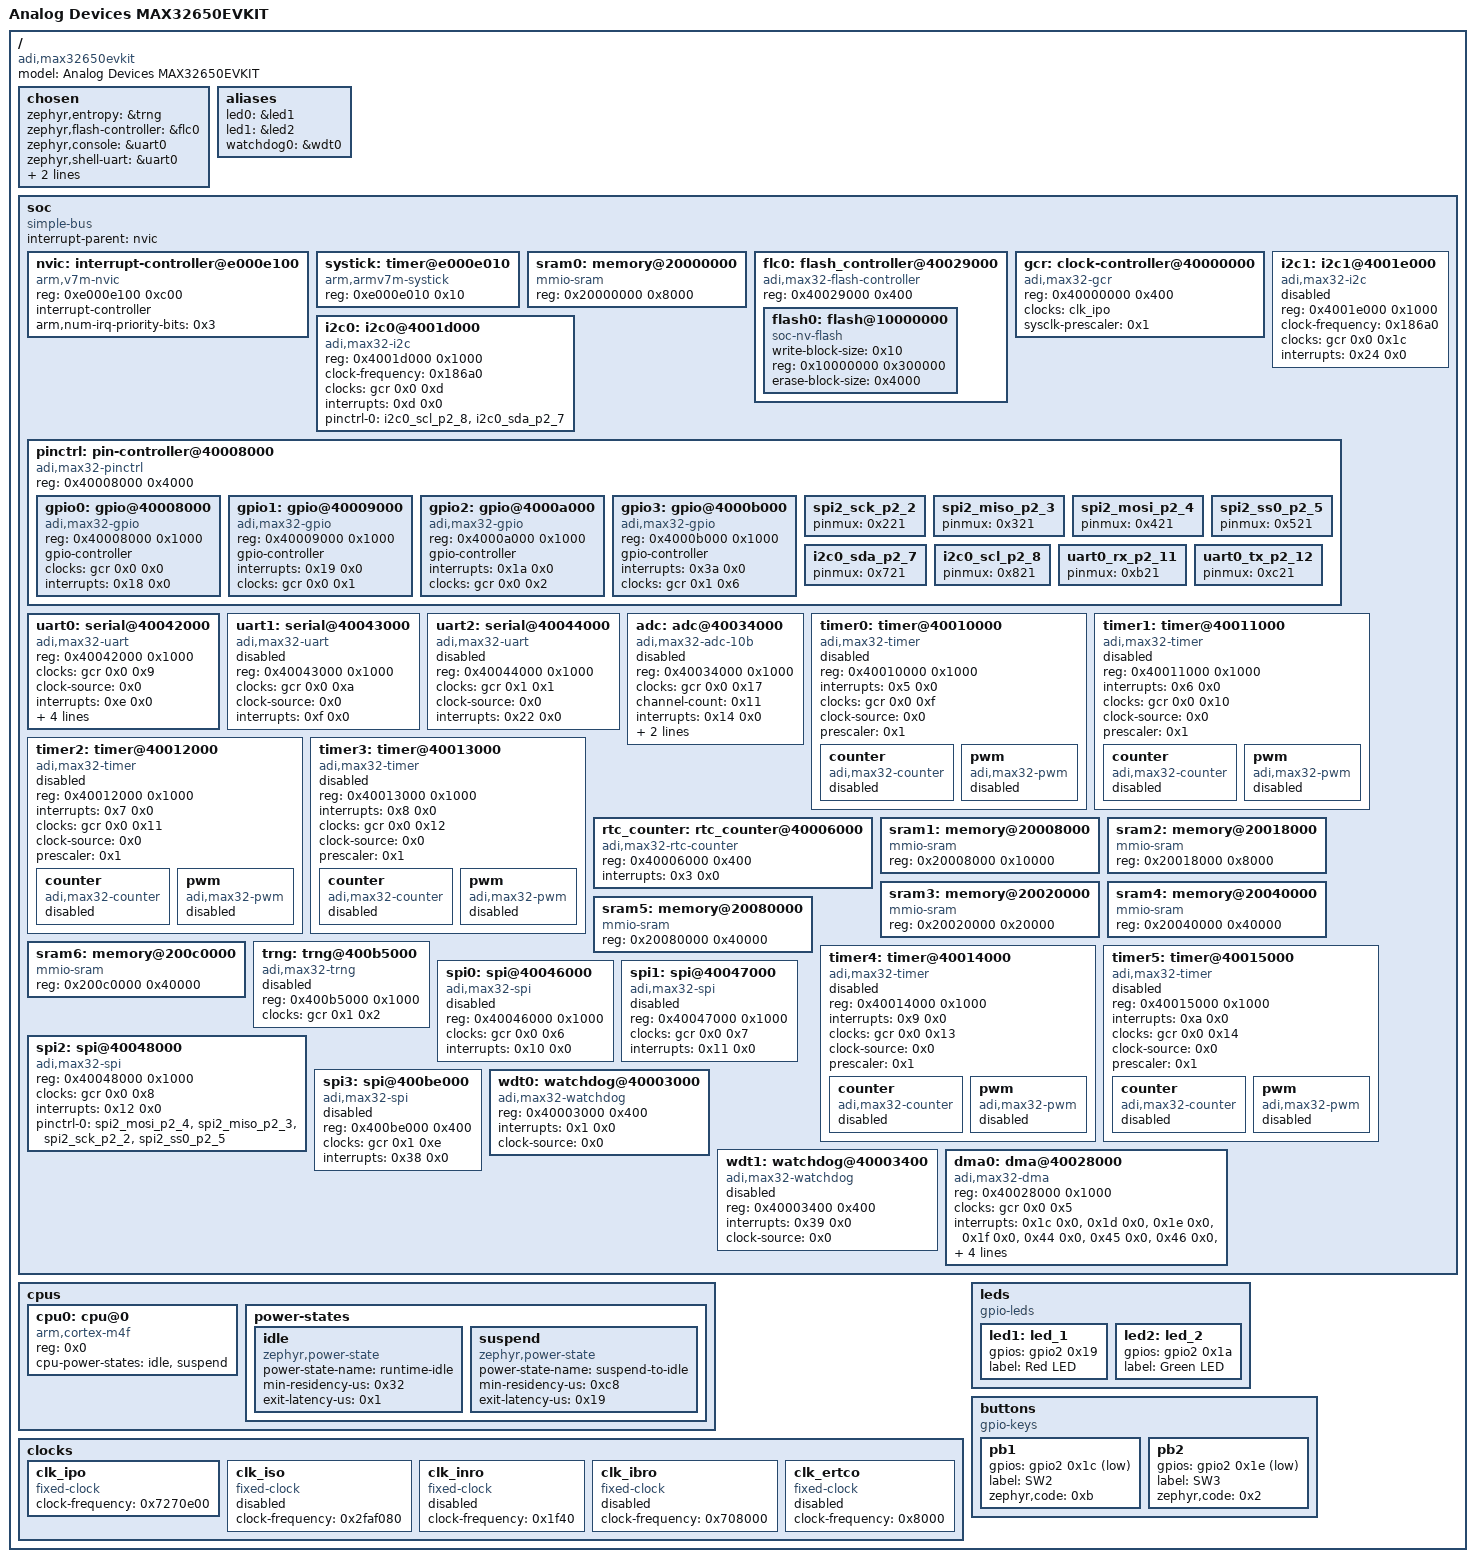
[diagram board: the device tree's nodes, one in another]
/dts-v1/;

/* node '/' defined in zephyr/dts/common/skeleton.dtsi:9 */
/ {
	#address-cells = < 0x1 >;               /* in zephyr/dts/common/skeleton.dtsi:10 */
	#size-cells = < 0x1 >;                  /* in zephyr/dts/common/skeleton.dtsi:11 */
	model = "Analog Devices MAX32650EVKIT"; /* in zephyr/boards/adi/max32650evkit/max32650evkit.dts:15 */
	compatible = "adi,max32650evkit";       /* in zephyr/boards/adi/max32650evkit/max32650evkit.dts:16 */

	/* node '/chosen' defined in zephyr/dts/common/skeleton.dtsi:13 */
	chosen {
		zephyr,entropy = &trng;          /* in zephyr/dts/arm/adi/max32/max32xxx.dtsi:17 */
		zephyr,flash-controller = &flc0; /* in zephyr/dts/arm/adi/max32/max32xxx.dtsi:18 */
		zephyr,console = &uart0;         /* in zephyr/boards/adi/max32650evkit/max32650evkit.dts:19 */
		zephyr,shell-uart = &uart0;      /* in zephyr/boards/adi/max32650evkit/max32650evkit.dts:20 */
		zephyr,sram = &sram4;            /* in zephyr/boards/adi/max32650evkit/max32650evkit.dts:21 */
		zephyr,flash = &flash0;          /* in zephyr/boards/adi/max32650evkit/max32650evkit.dts:22 */
	};

	/* node '/aliases' defined in zephyr/dts/common/skeleton.dtsi:15 */
	aliases {
		led0 = &led1;      /* in zephyr/boards/adi/max32650evkit/max32650evkit.dts:57 */
		led1 = &led2;      /* in zephyr/boards/adi/max32650evkit/max32650evkit.dts:58 */
		watchdog0 = &wdt0; /* in zephyr/boards/adi/max32650evkit/max32650evkit.dts:59 */
	};

	/* node '/soc' defined in zephyr/dts/arm/armv7-m.dtsi:6 */
	soc {
		#address-cells = < 0x1 >;     /* in zephyr/dts/arm/armv7-m.dtsi:7 */
		#size-cells = < 0x1 >;        /* in zephyr/dts/arm/armv7-m.dtsi:8 */
		compatible = "simple-bus";    /* in zephyr/dts/arm/armv7-m.dtsi:9 */
		interrupt-parent = < &nvic >; /* in zephyr/dts/arm/armv7-m.dtsi:10 */
		ranges;                       /* in zephyr/dts/arm/armv7-m.dtsi:11 */

		/* node '/soc/interrupt-controller@e000e100' defined in zephyr/dts/arm/armv7-m.dtsi:13 */
		nvic: interrupt-controller@e000e100 {
			#address-cells = < 0x1 >;            /* in zephyr/dts/arm/armv7-m.dtsi:14 */
			compatible = "arm,v7m-nvic";         /* in zephyr/dts/arm/armv7-m.dtsi:15 */
			reg = < 0xe000e100 0xc00 >;          /* in zephyr/dts/arm/armv7-m.dtsi:16 */
			interrupt-controller;                /* in zephyr/dts/arm/armv7-m.dtsi:17 */
			#interrupt-cells = < 0x2 >;          /* in zephyr/dts/arm/armv7-m.dtsi:18 */
			arm,num-irq-priority-bits = < 0x3 >; /* in zephyr/dts/arm/adi/max32/max32xxx.dtsi:337 */
			phandle = < 0x1 >;                   /* in zephyr/dts/arm/armv7-m.dtsi:10 */
		};

		/* node '/soc/timer@e000e010' defined in zephyr/dts/arm/armv7-m.dtsi:21 */
		systick: timer@e000e010 {
			compatible = "arm,armv7m-systick"; /* in zephyr/dts/arm/armv7-m.dtsi:22 */
			reg = < 0xe000e010 0x10 >;         /* in zephyr/dts/arm/armv7-m.dtsi:23 */
		};

		/* node '/soc/memory@20000000' defined in zephyr/dts/arm/adi/max32/max32xxx.dtsi:98 */
		sram0: memory@20000000 {
			compatible = "mmio-sram";    /* in zephyr/dts/arm/adi/max32/max32xxx.dtsi:99 */
			reg = < 0x20000000 0x8000 >; /* in zephyr/dts/arm/adi/max32/max32xxx.dtsi:100 */
		};

		/* node '/soc/flash_controller@40029000' defined in zephyr/dts/arm/adi/max32/max32xxx.dtsi:103 */
		flc0: flash_controller@40029000 {
			compatible = "adi,max32-flash-controller"; /* in zephyr/dts/arm/adi/max32/max32xxx.dtsi:104 */
			reg = < 0x40029000 0x400 >;                /* in zephyr/dts/arm/adi/max32/max32xxx.dtsi:105 */
			#address-cells = < 0x1 >;                  /* in zephyr/dts/arm/adi/max32/max32xxx.dtsi:107 */
			#size-cells = < 0x1 >;                     /* in zephyr/dts/arm/adi/max32/max32xxx.dtsi:108 */
			status = "okay";                           /* in zephyr/dts/arm/adi/max32/max32xxx.dtsi:109 */

			/* node '/soc/flash_controller@40029000/flash@10000000' defined in zephyr/dts/arm/adi/max32/max32xxx.dtsi:111 */
			flash0: flash@10000000 {
				compatible = "soc-nv-flash";   /* in zephyr/dts/arm/adi/max32/max32xxx.dtsi:112 */
				write-block-size = < 0x10 >;   /* in zephyr/dts/arm/adi/max32/max32xxx.dtsi:114 */
				reg = < 0x10000000 0x300000 >; /* in zephyr/dts/arm/adi/max32/max32650.dtsi:12 */
				erase-block-size = < 0x4000 >; /* in zephyr/dts/arm/adi/max32/max32650.dtsi:13 */
			};
		};

		/* node '/soc/clock-controller@40000000' defined in zephyr/dts/arm/adi/max32/max32xxx.dtsi:119 */
		gcr: clock-controller@40000000 {
			reg = < 0x40000000 0x400 >;   /* in zephyr/dts/arm/adi/max32/max32xxx.dtsi:120 */
			compatible = "adi,max32-gcr"; /* in zephyr/dts/arm/adi/max32/max32xxx.dtsi:121 */
			#clock-cells = < 0x2 >;       /* in zephyr/dts/arm/adi/max32/max32xxx.dtsi:122 */
			clocks = < &clk_ipo >;        /* in zephyr/dts/arm/adi/max32/max32xxx.dtsi:123 */
			sysclk-prescaler = < 0x1 >;   /* in zephyr/dts/arm/adi/max32/max32xxx.dtsi:124 */
			status = "okay";              /* in zephyr/dts/arm/adi/max32/max32xxx.dtsi:125 */
			phandle = < 0x3 >;            /* in zephyr/dts/arm/adi/max32/max32xxx.dtsi:134 */
		};

		/* node '/soc/i2c0@4001d000' defined in zephyr/dts/arm/adi/max32/max32xxx.dtsi:128 */
		i2c0: i2c0@4001d000 {
			compatible = "adi,max32-i2c";                  /* in zephyr/dts/arm/adi/max32/max32xxx.dtsi:129 */
			reg = < 0x4001d000 0x1000 >;                   /* in zephyr/dts/arm/adi/max32/max32xxx.dtsi:130 */
			#address-cells = < 0x1 >;                      /* in zephyr/dts/arm/adi/max32/max32xxx.dtsi:131 */
			#size-cells = < 0x0 >;                         /* in zephyr/dts/arm/adi/max32/max32xxx.dtsi:132 */
			clock-frequency = < 0x186a0 >;                 /* in zephyr/dts/arm/adi/max32/max32xxx.dtsi:133 */
			clocks = < &gcr 0x0 0xd >;                     /* in zephyr/dts/arm/adi/max32/max32xxx.dtsi:134 */
			interrupts = < 0xd 0x0 >;                      /* in zephyr/dts/arm/adi/max32/max32xxx.dtsi:135 */
			pinctrl-0 = < &i2c0_scl_p2_8 &i2c0_sda_p2_7 >; /* in zephyr/boards/adi/max32650evkit/max32650evkit.dts:97 */
			pinctrl-names = "default";                     /* in zephyr/boards/adi/max32650evkit/max32650evkit.dts:98 */
			status = "okay";                               /* in zephyr/boards/adi/max32650evkit/max32650evkit.dts:99 */
		};

		/* node '/soc/i2c1@4001e000' defined in zephyr/dts/arm/adi/max32/max32xxx.dtsi:139 */
		i2c1: i2c1@4001e000 {
			compatible = "adi,max32-i2c";  /* in zephyr/dts/arm/adi/max32/max32xxx.dtsi:140 */
			reg = < 0x4001e000 0x1000 >;   /* in zephyr/dts/arm/adi/max32/max32xxx.dtsi:141 */
			#address-cells = < 0x1 >;      /* in zephyr/dts/arm/adi/max32/max32xxx.dtsi:142 */
			#size-cells = < 0x0 >;         /* in zephyr/dts/arm/adi/max32/max32xxx.dtsi:143 */
			clock-frequency = < 0x186a0 >; /* in zephyr/dts/arm/adi/max32/max32xxx.dtsi:144 */
			clocks = < &gcr 0x0 0x1c >;    /* in zephyr/dts/arm/adi/max32/max32xxx.dtsi:145 */
			interrupts = < 0x24 0x0 >;     /* in zephyr/dts/arm/adi/max32/max32xxx.dtsi:146 */
			status = "disabled";           /* in zephyr/dts/arm/adi/max32/max32xxx.dtsi:147 */
		};

		/* node '/soc/pin-controller@40008000' defined in zephyr/dts/arm/adi/max32/max32xxx.dtsi:161 */
		pinctrl: pin-controller@40008000 {
			compatible = "adi,max32-pinctrl"; /* in zephyr/dts/arm/adi/max32/max32xxx.dtsi:162 */
			#address-cells = < 0x1 >;         /* in zephyr/dts/arm/adi/max32/max32xxx.dtsi:163 */
			#size-cells = < 0x1 >;            /* in zephyr/dts/arm/adi/max32/max32xxx.dtsi:164 */
			reg = < 0x40008000 0x4000 >;      /* in zephyr/dts/arm/adi/max32/max32650.dtsi:33 */

			/* node '/soc/pin-controller@40008000/gpio@40008000' defined in zephyr/dts/arm/adi/max32/max32xxx.dtsi:167 */
			gpio0: gpio@40008000 {
				reg = < 0x40008000 0x1000 >;   /* in zephyr/dts/arm/adi/max32/max32xxx.dtsi:168 */
				compatible = "adi,max32-gpio"; /* in zephyr/dts/arm/adi/max32/max32xxx.dtsi:169 */
				gpio-controller;               /* in zephyr/dts/arm/adi/max32/max32xxx.dtsi:170 */
				#gpio-cells = < 0x2 >;         /* in zephyr/dts/arm/adi/max32/max32xxx.dtsi:171 */
				clocks = < &gcr 0x0 0x0 >;     /* in zephyr/dts/arm/adi/max32/max32xxx.dtsi:172 */
				interrupts = < 0x18 0x0 >;     /* in zephyr/dts/arm/adi/max32/max32xxx.dtsi:173 */
				status = "okay";               /* in zephyr/boards/adi/max32650evkit/max32650evkit.dts:77 */
			};

			/* node '/soc/pin-controller@40008000/gpio@40009000' defined in zephyr/dts/arm/adi/max32/max32xxx.dtsi:177 */
			gpio1: gpio@40009000 {
				reg = < 0x40009000 0x1000 >;   /* in zephyr/dts/arm/adi/max32/max32xxx.dtsi:178 */
				compatible = "adi,max32-gpio"; /* in zephyr/dts/arm/adi/max32/max32xxx.dtsi:179 */
				gpio-controller;               /* in zephyr/dts/arm/adi/max32/max32xxx.dtsi:180 */
				#gpio-cells = < 0x2 >;         /* in zephyr/dts/arm/adi/max32/max32xxx.dtsi:181 */
				interrupts = < 0x19 0x0 >;     /* in zephyr/dts/arm/adi/max32/max32xxx.dtsi:182 */
				clocks = < &gcr 0x0 0x1 >;     /* in zephyr/dts/arm/adi/max32/max32xxx.dtsi:183 */
				status = "okay";               /* in zephyr/boards/adi/max32650evkit/max32650evkit.dts:81 */
			};

			/* node '/soc/pin-controller@40008000/gpio@4000a000' defined in zephyr/dts/arm/adi/max32/max32650.dtsi:35 */
			gpio2: gpio@4000a000 {
				reg = < 0x4000a000 0x1000 >;   /* in zephyr/dts/arm/adi/max32/max32650.dtsi:36 */
				compatible = "adi,max32-gpio"; /* in zephyr/dts/arm/adi/max32/max32650.dtsi:37 */
				gpio-controller;               /* in zephyr/dts/arm/adi/max32/max32650.dtsi:38 */
				#gpio-cells = < 0x2 >;         /* in zephyr/dts/arm/adi/max32/max32650.dtsi:39 */
				interrupts = < 0x1a 0x0 >;     /* in zephyr/dts/arm/adi/max32/max32650.dtsi:40 */
				clocks = < &gcr 0x0 0x2 >;     /* in zephyr/dts/arm/adi/max32/max32650.dtsi:41 */
				status = "okay";               /* in zephyr/boards/adi/max32650evkit/max32650evkit.dts:85 */
				phandle = < 0xe >;             /* in zephyr/boards/adi/max32650evkit/max32650evkit.dts:29 */
			};

			/* node '/soc/pin-controller@40008000/gpio@4000b000' defined in zephyr/dts/arm/adi/max32/max32650.dtsi:45 */
			gpio3: gpio@4000b000 {
				reg = < 0x4000b000 0x1000 >;   /* in zephyr/dts/arm/adi/max32/max32650.dtsi:46 */
				compatible = "adi,max32-gpio"; /* in zephyr/dts/arm/adi/max32/max32650.dtsi:47 */
				gpio-controller;               /* in zephyr/dts/arm/adi/max32/max32650.dtsi:48 */
				#gpio-cells = < 0x2 >;         /* in zephyr/dts/arm/adi/max32/max32650.dtsi:49 */
				interrupts = < 0x3a 0x0 >;     /* in zephyr/dts/arm/adi/max32/max32650.dtsi:50 */
				clocks = < &gcr 0x1 0x6 >;     /* in zephyr/dts/arm/adi/max32/max32650.dtsi:51 */
				status = "okay";               /* in zephyr/boards/adi/max32650evkit/max32650evkit.dts:89 */
			};

			/* node '/soc/pin-controller@40008000/spi2_sck_p2_2' defined in zephyr/dts/arm/adi/max32/max32650-pinctrl.dtsi:448 */
			spi2_sck_p2_2: spi2_sck_p2_2 {
				pinmux = < 0x221 >; /* in zephyr/dts/arm/adi/max32/max32650-pinctrl.dtsi:449 */
				phandle = < 0xa >;  /* in zephyr/boards/adi/max32650evkit/max32650evkit.dts:104 */
			};

			/* node '/soc/pin-controller@40008000/spi2_miso_p2_3' defined in zephyr/dts/arm/adi/max32/max32650-pinctrl.dtsi:456 */
			spi2_miso_p2_3: spi2_miso_p2_3 {
				pinmux = < 0x321 >; /* in zephyr/dts/arm/adi/max32/max32650-pinctrl.dtsi:457 */
				phandle = < 0x9 >;  /* in zephyr/boards/adi/max32650evkit/max32650evkit.dts:104 */
			};

			/* node '/soc/pin-controller@40008000/spi2_mosi_p2_4' defined in zephyr/dts/arm/adi/max32/max32650-pinctrl.dtsi:464 */
			spi2_mosi_p2_4: spi2_mosi_p2_4 {
				pinmux = < 0x421 >; /* in zephyr/dts/arm/adi/max32/max32650-pinctrl.dtsi:465 */
				phandle = < 0x8 >;  /* in zephyr/boards/adi/max32650evkit/max32650evkit.dts:104 */
			};

			/* node '/soc/pin-controller@40008000/spi2_ss0_p2_5' defined in zephyr/dts/arm/adi/max32/max32650-pinctrl.dtsi:468 */
			spi2_ss0_p2_5: spi2_ss0_p2_5 {
				pinmux = < 0x521 >; /* in zephyr/dts/arm/adi/max32/max32650-pinctrl.dtsi:469 */
				phandle = < 0xb >;  /* in zephyr/boards/adi/max32650evkit/max32650evkit.dts:104 */
			};

			/* node '/soc/pin-controller@40008000/i2c0_sda_p2_7' defined in zephyr/dts/arm/adi/max32/max32650-pinctrl.dtsi:484 */
			i2c0_sda_p2_7: i2c0_sda_p2_7 {
				pinmux = < 0x721 >; /* in zephyr/dts/arm/adi/max32/max32650-pinctrl.dtsi:485 */
				phandle = < 0x5 >;  /* in zephyr/boards/adi/max32650evkit/max32650evkit.dts:97 */
			};

			/* node '/soc/pin-controller@40008000/i2c0_scl_p2_8' defined in zephyr/dts/arm/adi/max32/max32650-pinctrl.dtsi:488 */
			i2c0_scl_p2_8: i2c0_scl_p2_8 {
				pinmux = < 0x821 >; /* in zephyr/dts/arm/adi/max32/max32650-pinctrl.dtsi:489 */
				phandle = < 0x4 >;  /* in zephyr/boards/adi/max32650evkit/max32650evkit.dts:97 */
			};

			/* node '/soc/pin-controller@40008000/uart0_rx_p2_11' defined in zephyr/dts/arm/adi/max32/max32650-pinctrl.dtsi:508 */
			uart0_rx_p2_11: uart0_rx_p2_11 {
				pinmux = < 0xb21 >; /* in zephyr/dts/arm/adi/max32/max32650-pinctrl.dtsi:509 */
				phandle = < 0x7 >;  /* in zephyr/boards/adi/max32650evkit/max32650evkit.dts:64 */
			};

			/* node '/soc/pin-controller@40008000/uart0_tx_p2_12' defined in zephyr/dts/arm/adi/max32/max32650-pinctrl.dtsi:516 */
			uart0_tx_p2_12: uart0_tx_p2_12 {
				pinmux = < 0xc21 >; /* in zephyr/dts/arm/adi/max32/max32650-pinctrl.dtsi:517 */
				phandle = < 0x6 >;  /* in zephyr/boards/adi/max32650evkit/max32650evkit.dts:64 */
			};
		};

		/* node '/soc/serial@40042000' defined in zephyr/dts/arm/adi/max32/max32xxx.dtsi:188 */
		uart0: serial@40042000 {
			compatible = "adi,max32-uart";                   /* in zephyr/dts/arm/adi/max32/max32xxx.dtsi:189 */
			reg = < 0x40042000 0x1000 >;                     /* in zephyr/dts/arm/adi/max32/max32xxx.dtsi:190 */
			clocks = < &gcr 0x0 0x9 >;                       /* in zephyr/dts/arm/adi/max32/max32xxx.dtsi:191 */
			clock-source = < 0x0 >;                          /* in zephyr/dts/arm/adi/max32/max32xxx.dtsi:192 */
			interrupts = < 0xe 0x0 >;                        /* in zephyr/dts/arm/adi/max32/max32xxx.dtsi:193 */
			pinctrl-0 = < &uart0_tx_p2_12 &uart0_rx_p2_11 >; /* in zephyr/boards/adi/max32650evkit/max32650evkit.dts:64 */
			pinctrl-names = "default";                       /* in zephyr/boards/adi/max32650evkit/max32650evkit.dts:65 */
			current-speed = < 0x1c200 >;                     /* in zephyr/boards/adi/max32650evkit/max32650evkit.dts:66 */
			data-bits = < 0x8 >;                             /* in zephyr/boards/adi/max32650evkit/max32650evkit.dts:67 */
			parity = "none";                                 /* in zephyr/boards/adi/max32650evkit/max32650evkit.dts:68 */
			status = "okay";                                 /* in zephyr/boards/adi/max32650evkit/max32650evkit.dts:69 */
		};

		/* node '/soc/serial@40043000' defined in zephyr/dts/arm/adi/max32/max32xxx.dtsi:197 */
		uart1: serial@40043000 {
			compatible = "adi,max32-uart"; /* in zephyr/dts/arm/adi/max32/max32xxx.dtsi:198 */
			reg = < 0x40043000 0x1000 >;   /* in zephyr/dts/arm/adi/max32/max32xxx.dtsi:199 */
			clocks = < &gcr 0x0 0xa >;     /* in zephyr/dts/arm/adi/max32/max32xxx.dtsi:200 */
			clock-source = < 0x0 >;        /* in zephyr/dts/arm/adi/max32/max32xxx.dtsi:201 */
			interrupts = < 0xf 0x0 >;      /* in zephyr/dts/arm/adi/max32/max32xxx.dtsi:202 */
			status = "disabled";           /* in zephyr/dts/arm/adi/max32/max32xxx.dtsi:203 */
		};

		/* node '/soc/serial@40044000' defined in zephyr/dts/arm/adi/max32/max32xxx.dtsi:206 */
		uart2: serial@40044000 {
			compatible = "adi,max32-uart"; /* in zephyr/dts/arm/adi/max32/max32xxx.dtsi:207 */
			reg = < 0x40044000 0x1000 >;   /* in zephyr/dts/arm/adi/max32/max32xxx.dtsi:208 */
			clocks = < &gcr 0x1 0x1 >;     /* in zephyr/dts/arm/adi/max32/max32xxx.dtsi:209 */
			clock-source = < 0x0 >;        /* in zephyr/dts/arm/adi/max32/max32xxx.dtsi:210 */
			interrupts = < 0x22 0x0 >;     /* in zephyr/dts/arm/adi/max32/max32xxx.dtsi:211 */
			status = "disabled";           /* in zephyr/dts/arm/adi/max32/max32xxx.dtsi:212 */
		};

		/* node '/soc/adc@40034000' defined in zephyr/dts/arm/adi/max32/max32xxx.dtsi:231 */
		adc: adc@40034000 {
			compatible = "adi,max32-adc-10b",
			             "adi,max32-adc";     /* in zephyr/dts/arm/adi/max32/max32xxx.dtsi:232 */
			reg = < 0x40034000 0x1000 >;      /* in zephyr/dts/arm/adi/max32/max32xxx.dtsi:233 */
			clocks = < &gcr 0x0 0x17 >;       /* in zephyr/dts/arm/adi/max32/max32xxx.dtsi:234 */
			channel-count = < 0x11 >;         /* in zephyr/dts/arm/adi/max32/max32xxx.dtsi:235 */
			#io-channel-cells = < 0x1 >;      /* in zephyr/dts/arm/adi/max32/max32xxx.dtsi:236 */
			interrupts = < 0x14 0x0 >;        /* in zephyr/dts/arm/adi/max32/max32xxx.dtsi:237 */
			resolution = < 0xa >;             /* in zephyr/dts/arm/adi/max32/max32xxx.dtsi:238 */
			vref-mv = < 0x4c4 >;              /* in zephyr/dts/arm/adi/max32/max32xxx.dtsi:239 */
			status = "disabled";              /* in zephyr/dts/arm/adi/max32/max32xxx.dtsi:240 */
		};

		/* node '/soc/timer@40010000' defined in zephyr/dts/arm/adi/max32/max32xxx.dtsi:243 */
		timer0: timer@40010000 {
			compatible = "adi,max32-timer"; /* in zephyr/dts/arm/adi/max32/max32xxx.dtsi:244 */
			reg = < 0x40010000 0x1000 >;    /* in zephyr/dts/arm/adi/max32/max32xxx.dtsi:245 */
			interrupts = < 0x5 0x0 >;       /* in zephyr/dts/arm/adi/max32/max32xxx.dtsi:246 */
			status = "disabled";            /* in zephyr/dts/arm/adi/max32/max32xxx.dtsi:247 */
			clocks = < &gcr 0x0 0xf >;      /* in zephyr/dts/arm/adi/max32/max32xxx.dtsi:248 */
			clock-source = < 0x0 >;         /* in zephyr/dts/arm/adi/max32/max32xxx.dtsi:249 */
			prescaler = < 0x1 >;            /* in zephyr/dts/arm/adi/max32/max32xxx.dtsi:250 */

			/* node '/soc/timer@40010000/counter' defined in zephyr/dts/arm/adi/max32/max32xxx.dtsi:252 */
			counter {
				compatible = "adi,max32-counter"; /* in zephyr/dts/arm/adi/max32/max32xxx.dtsi:253 */
				status = "disabled";              /* in zephyr/dts/arm/adi/max32/max32xxx.dtsi:254 */
			};

			/* node '/soc/timer@40010000/pwm' defined in zephyr/dts/arm/adi/max32/max32xxx.dtsi:257 */
			pwm {
				compatible = "adi,max32-pwm"; /* in zephyr/dts/arm/adi/max32/max32xxx.dtsi:258 */
				status = "disabled";          /* in zephyr/dts/arm/adi/max32/max32xxx.dtsi:259 */
				#pwm-cells = < 0x3 >;         /* in zephyr/dts/arm/adi/max32/max32xxx.dtsi:260 */
			};
		};

		/* node '/soc/timer@40011000' defined in zephyr/dts/arm/adi/max32/max32xxx.dtsi:264 */
		timer1: timer@40011000 {
			compatible = "adi,max32-timer"; /* in zephyr/dts/arm/adi/max32/max32xxx.dtsi:265 */
			reg = < 0x40011000 0x1000 >;    /* in zephyr/dts/arm/adi/max32/max32xxx.dtsi:266 */
			interrupts = < 0x6 0x0 >;       /* in zephyr/dts/arm/adi/max32/max32xxx.dtsi:267 */
			status = "disabled";            /* in zephyr/dts/arm/adi/max32/max32xxx.dtsi:268 */
			clocks = < &gcr 0x0 0x10 >;     /* in zephyr/dts/arm/adi/max32/max32xxx.dtsi:269 */
			clock-source = < 0x0 >;         /* in zephyr/dts/arm/adi/max32/max32xxx.dtsi:270 */
			prescaler = < 0x1 >;            /* in zephyr/dts/arm/adi/max32/max32xxx.dtsi:271 */

			/* node '/soc/timer@40011000/counter' defined in zephyr/dts/arm/adi/max32/max32xxx.dtsi:273 */
			counter {
				compatible = "adi,max32-counter"; /* in zephyr/dts/arm/adi/max32/max32xxx.dtsi:274 */
				status = "disabled";              /* in zephyr/dts/arm/adi/max32/max32xxx.dtsi:275 */
			};

			/* node '/soc/timer@40011000/pwm' defined in zephyr/dts/arm/adi/max32/max32xxx.dtsi:278 */
			pwm {
				compatible = "adi,max32-pwm"; /* in zephyr/dts/arm/adi/max32/max32xxx.dtsi:279 */
				status = "disabled";          /* in zephyr/dts/arm/adi/max32/max32xxx.dtsi:280 */
				#pwm-cells = < 0x3 >;         /* in zephyr/dts/arm/adi/max32/max32xxx.dtsi:281 */
			};
		};

		/* node '/soc/timer@40012000' defined in zephyr/dts/arm/adi/max32/max32xxx.dtsi:285 */
		timer2: timer@40012000 {
			compatible = "adi,max32-timer"; /* in zephyr/dts/arm/adi/max32/max32xxx.dtsi:286 */
			reg = < 0x40012000 0x1000 >;    /* in zephyr/dts/arm/adi/max32/max32xxx.dtsi:287 */
			interrupts = < 0x7 0x0 >;       /* in zephyr/dts/arm/adi/max32/max32xxx.dtsi:288 */
			status = "disabled";            /* in zephyr/dts/arm/adi/max32/max32xxx.dtsi:289 */
			clocks = < &gcr 0x0 0x11 >;     /* in zephyr/dts/arm/adi/max32/max32xxx.dtsi:290 */
			clock-source = < 0x0 >;         /* in zephyr/dts/arm/adi/max32/max32xxx.dtsi:291 */
			prescaler = < 0x1 >;            /* in zephyr/dts/arm/adi/max32/max32xxx.dtsi:292 */

			/* node '/soc/timer@40012000/counter' defined in zephyr/dts/arm/adi/max32/max32xxx.dtsi:294 */
			counter {
				compatible = "adi,max32-counter"; /* in zephyr/dts/arm/adi/max32/max32xxx.dtsi:295 */
				status = "disabled";              /* in zephyr/dts/arm/adi/max32/max32xxx.dtsi:296 */
			};

			/* node '/soc/timer@40012000/pwm' defined in zephyr/dts/arm/adi/max32/max32xxx.dtsi:299 */
			pwm {
				compatible = "adi,max32-pwm"; /* in zephyr/dts/arm/adi/max32/max32xxx.dtsi:300 */
				status = "disabled";          /* in zephyr/dts/arm/adi/max32/max32xxx.dtsi:301 */
				#pwm-cells = < 0x3 >;         /* in zephyr/dts/arm/adi/max32/max32xxx.dtsi:302 */
			};
		};

		/* node '/soc/timer@40013000' defined in zephyr/dts/arm/adi/max32/max32xxx.dtsi:306 */
		timer3: timer@40013000 {
			compatible = "adi,max32-timer"; /* in zephyr/dts/arm/adi/max32/max32xxx.dtsi:307 */
			reg = < 0x40013000 0x1000 >;    /* in zephyr/dts/arm/adi/max32/max32xxx.dtsi:308 */
			interrupts = < 0x8 0x0 >;       /* in zephyr/dts/arm/adi/max32/max32xxx.dtsi:309 */
			status = "disabled";            /* in zephyr/dts/arm/adi/max32/max32xxx.dtsi:310 */
			clocks = < &gcr 0x0 0x12 >;     /* in zephyr/dts/arm/adi/max32/max32xxx.dtsi:311 */
			clock-source = < 0x0 >;         /* in zephyr/dts/arm/adi/max32/max32xxx.dtsi:312 */
			prescaler = < 0x1 >;            /* in zephyr/dts/arm/adi/max32/max32xxx.dtsi:313 */

			/* node '/soc/timer@40013000/counter' defined in zephyr/dts/arm/adi/max32/max32xxx.dtsi:315 */
			counter {
				compatible = "adi,max32-counter"; /* in zephyr/dts/arm/adi/max32/max32xxx.dtsi:316 */
				status = "disabled";              /* in zephyr/dts/arm/adi/max32/max32xxx.dtsi:317 */
			};

			/* node '/soc/timer@40013000/pwm' defined in zephyr/dts/arm/adi/max32/max32xxx.dtsi:320 */
			pwm {
				compatible = "adi,max32-pwm"; /* in zephyr/dts/arm/adi/max32/max32xxx.dtsi:321 */
				status = "disabled";          /* in zephyr/dts/arm/adi/max32/max32xxx.dtsi:322 */
				#pwm-cells = < 0x3 >;         /* in zephyr/dts/arm/adi/max32/max32xxx.dtsi:323 */
			};
		};

		/* node '/soc/rtc_counter@40006000' defined in zephyr/dts/arm/adi/max32/max32xxx.dtsi:327 */
		rtc_counter: rtc_counter@40006000 {
			compatible = "adi,max32-rtc-counter"; /* in zephyr/dts/arm/adi/max32/max32xxx.dtsi:328 */
			reg = < 0x40006000 0x400 >;           /* in zephyr/dts/arm/adi/max32/max32xxx.dtsi:329 */
			interrupts = < 0x3 0x0 >;             /* in zephyr/dts/arm/adi/max32/max32xxx.dtsi:330 */
			status = "okay";                      /* in zephyr/boards/adi/max32650evkit/max32650evkit.dts:113 */
		};

		/* node '/soc/memory@20008000' defined in zephyr/dts/arm/adi/max32/max32650.dtsi:59 */
		sram1: memory@20008000 {
			compatible = "mmio-sram";     /* in zephyr/dts/arm/adi/max32/max32650.dtsi:60 */
			reg = < 0x20008000 0x10000 >; /* in zephyr/dts/arm/adi/max32/max32650.dtsi:61 */
		};

		/* node '/soc/memory@20018000' defined in zephyr/dts/arm/adi/max32/max32650.dtsi:64 */
		sram2: memory@20018000 {
			compatible = "mmio-sram";    /* in zephyr/dts/arm/adi/max32/max32650.dtsi:65 */
			reg = < 0x20018000 0x8000 >; /* in zephyr/dts/arm/adi/max32/max32650.dtsi:66 */
		};

		/* node '/soc/memory@20020000' defined in zephyr/dts/arm/adi/max32/max32650.dtsi:69 */
		sram3: memory@20020000 {
			compatible = "mmio-sram";     /* in zephyr/dts/arm/adi/max32/max32650.dtsi:70 */
			reg = < 0x20020000 0x20000 >; /* in zephyr/dts/arm/adi/max32/max32650.dtsi:71 */
		};

		/* node '/soc/memory@20040000' defined in zephyr/dts/arm/adi/max32/max32650.dtsi:74 */
		sram4: memory@20040000 {
			compatible = "mmio-sram";     /* in zephyr/dts/arm/adi/max32/max32650.dtsi:75 */
			reg = < 0x20040000 0x40000 >; /* in zephyr/dts/arm/adi/max32/max32650.dtsi:76 */
		};

		/* node '/soc/memory@20080000' defined in zephyr/dts/arm/adi/max32/max32650.dtsi:79 */
		sram5: memory@20080000 {
			compatible = "mmio-sram";     /* in zephyr/dts/arm/adi/max32/max32650.dtsi:80 */
			reg = < 0x20080000 0x40000 >; /* in zephyr/dts/arm/adi/max32/max32650.dtsi:81 */
		};

		/* node '/soc/memory@200c0000' defined in zephyr/dts/arm/adi/max32/max32650.dtsi:84 */
		sram6: memory@200c0000 {
			compatible = "mmio-sram";     /* in zephyr/dts/arm/adi/max32/max32650.dtsi:85 */
			reg = < 0x200c0000 0x40000 >; /* in zephyr/dts/arm/adi/max32/max32650.dtsi:86 */
		};

		/* node '/soc/trng@400b5000' defined in zephyr/dts/arm/adi/max32/max32650.dtsi:89 */
		trng: trng@400b5000 {
			compatible = "adi,max32-trng"; /* in zephyr/dts/arm/adi/max32/max32650.dtsi:90 */
			reg = < 0x400b5000 0x1000 >;   /* in zephyr/dts/arm/adi/max32/max32650.dtsi:91 */
			clocks = < &gcr 0x1 0x2 >;     /* in zephyr/dts/arm/adi/max32/max32650.dtsi:92 */
			status = "disabled";           /* in zephyr/dts/arm/adi/max32/max32650.dtsi:93 */
		};

		/* node '/soc/timer@40014000' defined in zephyr/dts/arm/adi/max32/max32650.dtsi:96 */
		timer4: timer@40014000 {
			compatible = "adi,max32-timer"; /* in zephyr/dts/arm/adi/max32/max32650.dtsi:97 */
			reg = < 0x40014000 0x1000 >;    /* in zephyr/dts/arm/adi/max32/max32650.dtsi:98 */
			interrupts = < 0x9 0x0 >;       /* in zephyr/dts/arm/adi/max32/max32650.dtsi:99 */
			status = "disabled";            /* in zephyr/dts/arm/adi/max32/max32650.dtsi:100 */
			clocks = < &gcr 0x0 0x13 >;     /* in zephyr/dts/arm/adi/max32/max32650.dtsi:101 */
			clock-source = < 0x0 >;         /* in zephyr/dts/arm/adi/max32/max32650.dtsi:102 */
			prescaler = < 0x1 >;            /* in zephyr/dts/arm/adi/max32/max32650.dtsi:103 */

			/* node '/soc/timer@40014000/counter' defined in zephyr/dts/arm/adi/max32/max32650.dtsi:105 */
			counter {
				compatible = "adi,max32-counter"; /* in zephyr/dts/arm/adi/max32/max32650.dtsi:106 */
				status = "disabled";              /* in zephyr/dts/arm/adi/max32/max32650.dtsi:107 */
			};

			/* node '/soc/timer@40014000/pwm' defined in zephyr/dts/arm/adi/max32/max32650.dtsi:110 */
			pwm {
				compatible = "adi,max32-pwm"; /* in zephyr/dts/arm/adi/max32/max32650.dtsi:111 */
				status = "disabled";          /* in zephyr/dts/arm/adi/max32/max32650.dtsi:112 */
				#pwm-cells = < 0x3 >;         /* in zephyr/dts/arm/adi/max32/max32650.dtsi:113 */
			};
		};

		/* node '/soc/timer@40015000' defined in zephyr/dts/arm/adi/max32/max32650.dtsi:117 */
		timer5: timer@40015000 {
			compatible = "adi,max32-timer"; /* in zephyr/dts/arm/adi/max32/max32650.dtsi:118 */
			reg = < 0x40015000 0x1000 >;    /* in zephyr/dts/arm/adi/max32/max32650.dtsi:119 */
			interrupts = < 0xa 0x0 >;       /* in zephyr/dts/arm/adi/max32/max32650.dtsi:120 */
			status = "disabled";            /* in zephyr/dts/arm/adi/max32/max32650.dtsi:121 */
			clocks = < &gcr 0x0 0x14 >;     /* in zephyr/dts/arm/adi/max32/max32650.dtsi:122 */
			clock-source = < 0x0 >;         /* in zephyr/dts/arm/adi/max32/max32650.dtsi:123 */
			prescaler = < 0x1 >;            /* in zephyr/dts/arm/adi/max32/max32650.dtsi:124 */

			/* node '/soc/timer@40015000/counter' defined in zephyr/dts/arm/adi/max32/max32650.dtsi:126 */
			counter {
				compatible = "adi,max32-counter"; /* in zephyr/dts/arm/adi/max32/max32650.dtsi:127 */
				status = "disabled";              /* in zephyr/dts/arm/adi/max32/max32650.dtsi:128 */
			};

			/* node '/soc/timer@40015000/pwm' defined in zephyr/dts/arm/adi/max32/max32650.dtsi:131 */
			pwm {
				compatible = "adi,max32-pwm"; /* in zephyr/dts/arm/adi/max32/max32650.dtsi:132 */
				status = "disabled";          /* in zephyr/dts/arm/adi/max32/max32650.dtsi:133 */
				#pwm-cells = < 0x3 >;         /* in zephyr/dts/arm/adi/max32/max32650.dtsi:134 */
			};
		};

		/* node '/soc/spi@40046000' defined in zephyr/dts/arm/adi/max32/max32650.dtsi:138 */
		spi0: spi@40046000 {
			compatible = "adi,max32-spi"; /* in zephyr/dts/arm/adi/max32/max32650.dtsi:139 */
			reg = < 0x40046000 0x1000 >;  /* in zephyr/dts/arm/adi/max32/max32650.dtsi:140 */
			#address-cells = < 0x1 >;     /* in zephyr/dts/arm/adi/max32/max32650.dtsi:141 */
			#size-cells = < 0x0 >;        /* in zephyr/dts/arm/adi/max32/max32650.dtsi:142 */
			clocks = < &gcr 0x0 0x6 >;    /* in zephyr/dts/arm/adi/max32/max32650.dtsi:143 */
			interrupts = < 0x10 0x0 >;    /* in zephyr/dts/arm/adi/max32/max32650.dtsi:144 */
			status = "disabled";          /* in zephyr/dts/arm/adi/max32/max32650.dtsi:145 */
		};

		/* node '/soc/spi@40047000' defined in zephyr/dts/arm/adi/max32/max32650.dtsi:148 */
		spi1: spi@40047000 {
			compatible = "adi,max32-spi"; /* in zephyr/dts/arm/adi/max32/max32650.dtsi:149 */
			reg = < 0x40047000 0x1000 >;  /* in zephyr/dts/arm/adi/max32/max32650.dtsi:150 */
			#address-cells = < 0x1 >;     /* in zephyr/dts/arm/adi/max32/max32650.dtsi:151 */
			#size-cells = < 0x0 >;        /* in zephyr/dts/arm/adi/max32/max32650.dtsi:152 */
			clocks = < &gcr 0x0 0x7 >;    /* in zephyr/dts/arm/adi/max32/max32650.dtsi:153 */
			interrupts = < 0x11 0x0 >;    /* in zephyr/dts/arm/adi/max32/max32650.dtsi:154 */
			status = "disabled";          /* in zephyr/dts/arm/adi/max32/max32650.dtsi:155 */
		};

		/* node '/soc/spi@40048000' defined in zephyr/dts/arm/adi/max32/max32650.dtsi:158 */
		spi2: spi@40048000 {
			compatible = "adi,max32-spi";                                                  /* in zephyr/dts/arm/adi/max32/max32650.dtsi:159 */
			reg = < 0x40048000 0x1000 >;                                                   /* in zephyr/dts/arm/adi/max32/max32650.dtsi:160 */
			#address-cells = < 0x1 >;                                                      /* in zephyr/dts/arm/adi/max32/max32650.dtsi:161 */
			#size-cells = < 0x0 >;                                                         /* in zephyr/dts/arm/adi/max32/max32650.dtsi:162 */
			clocks = < &gcr 0x0 0x8 >;                                                     /* in zephyr/dts/arm/adi/max32/max32650.dtsi:163 */
			interrupts = < 0x12 0x0 >;                                                     /* in zephyr/dts/arm/adi/max32/max32650.dtsi:164 */
			status = "okay";                                                               /* in zephyr/boards/adi/max32650evkit/max32650evkit.dts:103 */
			pinctrl-0 = < &spi2_mosi_p2_4 &spi2_miso_p2_3 &spi2_sck_p2_2 &spi2_ss0_p2_5 >; /* in zephyr/boards/adi/max32650evkit/max32650evkit.dts:104 */
			pinctrl-names = "default";                                                     /* in zephyr/boards/adi/max32650evkit/max32650evkit.dts:105 */
		};

		/* node '/soc/spi@400be000' defined in zephyr/dts/arm/adi/max32/max32650.dtsi:168 */
		spi3: spi@400be000 {
			compatible = "adi,max32-spi"; /* in zephyr/dts/arm/adi/max32/max32650.dtsi:169 */
			reg = < 0x400be000 0x400 >;   /* in zephyr/dts/arm/adi/max32/max32650.dtsi:170 */
			#address-cells = < 0x1 >;     /* in zephyr/dts/arm/adi/max32/max32650.dtsi:171 */
			#size-cells = < 0x0 >;        /* in zephyr/dts/arm/adi/max32/max32650.dtsi:172 */
			clocks = < &gcr 0x1 0xe >;    /* in zephyr/dts/arm/adi/max32/max32650.dtsi:173 */
			interrupts = < 0x38 0x0 >;    /* in zephyr/dts/arm/adi/max32/max32650.dtsi:174 */
			status = "disabled";          /* in zephyr/dts/arm/adi/max32/max32650.dtsi:175 */
		};

		/* node '/soc/watchdog@40003000' defined in zephyr/dts/arm/adi/max32/max32650.dtsi:178 */
		wdt0: watchdog@40003000 {
			compatible = "adi,max32-watchdog"; /* in zephyr/dts/arm/adi/max32/max32650.dtsi:179 */
			reg = < 0x40003000 0x400 >;        /* in zephyr/dts/arm/adi/max32/max32650.dtsi:180 */
			interrupts = < 0x1 0x0 >;          /* in zephyr/dts/arm/adi/max32/max32650.dtsi:181 */
			clock-source = < 0x0 >;            /* in zephyr/dts/arm/adi/max32/max32650.dtsi:182 */
			status = "okay";                   /* in zephyr/boards/adi/max32650evkit/max32650evkit.dts:109 */
		};

		/* node '/soc/watchdog@40003400' defined in zephyr/dts/arm/adi/max32/max32650.dtsi:186 */
		wdt1: watchdog@40003400 {
			compatible = "adi,max32-watchdog"; /* in zephyr/dts/arm/adi/max32/max32650.dtsi:187 */
			reg = < 0x40003400 0x400 >;        /* in zephyr/dts/arm/adi/max32/max32650.dtsi:188 */
			interrupts = < 0x39 0x0 >;         /* in zephyr/dts/arm/adi/max32/max32650.dtsi:189 */
			clock-source = < 0x0 >;            /* in zephyr/dts/arm/adi/max32/max32650.dtsi:190 */
			status = "disabled";               /* in zephyr/dts/arm/adi/max32/max32650.dtsi:191 */
		};

		/* node '/soc/dma@40028000' defined in zephyr/dts/arm/adi/max32/max32650.dtsi:194 */
		dma0: dma@40028000 {
			compatible = "adi,max32-dma"; /* in zephyr/dts/arm/adi/max32/max32650.dtsi:195 */
			reg = < 0x40028000 0x1000 >;  /* in zephyr/dts/arm/adi/max32/max32650.dtsi:196 */
			clocks = < &gcr 0x0 0x5 >;    /* in zephyr/dts/arm/adi/max32/max32650.dtsi:197 */
			interrupts = < 0x1c 0x0 >,
			             < 0x1d 0x0 >,
			             < 0x1e 0x0 >,
			             < 0x1f 0x0 >,
			             < 0x44 0x0 >,
			             < 0x45 0x0 >,
			             < 0x46 0x0 >,
			             < 0x47 0x0 >,
			             < 0x48 0x0 >,
			             < 0x49 0x0 >,
			             < 0x4a 0x0 >,
			             < 0x4b 0x0 >,
			             < 0x4c 0x0 >,
			             < 0x4d 0x0 >,
			             < 0x4e 0x0 >,
			             < 0x4f 0x0 >;    /* in zephyr/dts/arm/adi/max32/max32650.dtsi:198 */
			dma-channels = < 0x10 >;      /* in zephyr/dts/arm/adi/max32/max32650.dtsi:200 */
			#dma-cells = < 0x2 >;         /* in zephyr/dts/arm/adi/max32/max32650.dtsi:202 */
			status = "okay";              /* in zephyr/boards/adi/max32650evkit/max32650evkit.dts:93 */
		};
	};

	/* node '/cpus' defined in zephyr/dts/arm/adi/max32/max32xxx.dtsi:21 */
	cpus {
		#address-cells = < 0x1 >; /* in zephyr/dts/arm/adi/max32/max32xxx.dtsi:22 */
		#size-cells = < 0x0 >;    /* in zephyr/dts/arm/adi/max32/max32xxx.dtsi:23 */

		/* node '/cpus/cpu@0' defined in zephyr/dts/arm/adi/max32/max32xxx.dtsi:25 */
		cpu0: cpu@0 {
			device_type = "cpu";                   /* in zephyr/dts/arm/adi/max32/max32xxx.dtsi:26 */
			compatible = "arm,cortex-m4f";         /* in zephyr/dts/arm/adi/max32/max32xxx.dtsi:27 */
			reg = < 0x0 >;                         /* in zephyr/dts/arm/adi/max32/max32xxx.dtsi:28 */
			cpu-power-states = < &idle &suspend >; /* in zephyr/dts/arm/adi/max32/max32xxx.dtsi:29 */
		};

		/* node '/cpus/power-states' defined in zephyr/dts/arm/adi/max32/max32xxx.dtsi:32 */
		power-states {

			/* node '/cpus/power-states/idle' defined in zephyr/dts/arm/adi/max32/max32xxx.dtsi:34 */
			idle: idle {
				compatible = "zephyr,power-state"; /* in zephyr/dts/arm/adi/max32/max32xxx.dtsi:35 */
				power-state-name = "runtime-idle"; /* in zephyr/dts/arm/adi/max32/max32xxx.dtsi:36 */
				min-residency-us = < 0x32 >;       /* in zephyr/dts/arm/adi/max32/max32xxx.dtsi:37 */
				exit-latency-us = < 0x1 >;         /* in zephyr/dts/arm/adi/max32/max32xxx.dtsi:39 */
				phandle = < 0xc >;                 /* in zephyr/dts/arm/adi/max32/max32xxx.dtsi:29 */
			};

			/* node '/cpus/power-states/suspend' defined in zephyr/dts/arm/adi/max32/max32xxx.dtsi:43 */
			suspend: suspend {
				compatible = "zephyr,power-state";    /* in zephyr/dts/arm/adi/max32/max32xxx.dtsi:44 */
				power-state-name = "suspend-to-idle"; /* in zephyr/dts/arm/adi/max32/max32xxx.dtsi:45 */
				min-residency-us = < 0xc8 >;          /* in zephyr/dts/arm/adi/max32/max32xxx.dtsi:46 */
				exit-latency-us = < 0x19 >;           /* in zephyr/dts/arm/adi/max32/max32xxx.dtsi:48 */
				phandle = < 0xd >;                    /* in zephyr/dts/arm/adi/max32/max32xxx.dtsi:29 */
			};
		};
	};

	/* node '/clocks' defined in zephyr/dts/arm/adi/max32/max32xxx.dtsi:53 */
	clocks {

		/* node '/clocks/clk_ipo' defined in zephyr/dts/arm/adi/max32/max32xxx.dtsi:54 */
		clk_ipo: clk_ipo {
			compatible = "fixed-clock";      /* in zephyr/dts/arm/adi/max32/max32xxx.dtsi:55 */
			#clock-cells = < 0x0 >;          /* in zephyr/dts/arm/adi/max32/max32xxx.dtsi:56 */
			clock-frequency = < 0x7270e00 >; /* in zephyr/dts/arm/adi/max32/max32650.dtsi:17 */
			status = "okay";                 /* in zephyr/boards/adi/max32650evkit/max32650evkit.dts:73 */
			phandle = < 0x2 >;               /* in zephyr/dts/arm/adi/max32/max32xxx.dtsi:123 */
		};

		/* node '/clocks/clk_iso' defined in zephyr/dts/arm/adi/max32/max32xxx.dtsi:61 */
		clk_iso: clk_iso {
			compatible = "fixed-clock";      /* in zephyr/dts/arm/adi/max32/max32xxx.dtsi:62 */
			#clock-cells = < 0x0 >;          /* in zephyr/dts/arm/adi/max32/max32xxx.dtsi:63 */
			status = "disabled";             /* in zephyr/dts/arm/adi/max32/max32xxx.dtsi:65 */
			clock-frequency = < 0x2faf080 >; /* in zephyr/dts/arm/adi/max32/max32650.dtsi:21 */
		};

		/* node '/clocks/clk_inro' defined in zephyr/dts/arm/adi/max32/max32xxx.dtsi:68 */
		clk_inro: clk_inro {
			compatible = "fixed-clock";   /* in zephyr/dts/arm/adi/max32/max32xxx.dtsi:69 */
			#clock-cells = < 0x0 >;       /* in zephyr/dts/arm/adi/max32/max32xxx.dtsi:70 */
			clock-frequency = < 0x1f40 >; /* in zephyr/dts/arm/adi/max32/max32xxx.dtsi:71 */
			status = "disabled";          /* in zephyr/dts/arm/adi/max32/max32xxx.dtsi:72 */
		};

		/* node '/clocks/clk_ibro' defined in zephyr/dts/arm/adi/max32/max32xxx.dtsi:75 */
		clk_ibro: clk_ibro {
			compatible = "fixed-clock";     /* in zephyr/dts/arm/adi/max32/max32xxx.dtsi:76 */
			#clock-cells = < 0x0 >;         /* in zephyr/dts/arm/adi/max32/max32xxx.dtsi:77 */
			clock-frequency = < 0x708000 >; /* in zephyr/dts/arm/adi/max32/max32xxx.dtsi:78 */
			status = "disabled";            /* in zephyr/dts/arm/adi/max32/max32xxx.dtsi:79 */
		};

		/* node '/clocks/clk_ertco' defined in zephyr/dts/arm/adi/max32/max32xxx.dtsi:82 */
		clk_ertco: clk_ertco {
			compatible = "fixed-clock";   /* in zephyr/dts/arm/adi/max32/max32xxx.dtsi:83 */
			#clock-cells = < 0x0 >;       /* in zephyr/dts/arm/adi/max32/max32xxx.dtsi:84 */
			clock-frequency = < 0x8000 >; /* in zephyr/dts/arm/adi/max32/max32xxx.dtsi:85 */
			status = "disabled";          /* in zephyr/dts/arm/adi/max32/max32xxx.dtsi:86 */
		};
	};

	/* node '/leds' defined in zephyr/boards/adi/max32650evkit/max32650evkit.dts:25 */
	leds {
		compatible = "gpio-leds"; /* in zephyr/boards/adi/max32650evkit/max32650evkit.dts:26 */

		/* node '/leds/led_1' defined in zephyr/boards/adi/max32650evkit/max32650evkit.dts:28 */
		led1: led_1 {
			gpios = < &gpio2 0x19 0x0 >; /* in zephyr/boards/adi/max32650evkit/max32650evkit.dts:29 */
			label = "Red LED";           /* in zephyr/boards/adi/max32650evkit/max32650evkit.dts:30 */
		};

		/* node '/leds/led_2' defined in zephyr/boards/adi/max32650evkit/max32650evkit.dts:33 */
		led2: led_2 {
			gpios = < &gpio2 0x1a 0x0 >; /* in zephyr/boards/adi/max32650evkit/max32650evkit.dts:34 */
			label = "Green LED";         /* in zephyr/boards/adi/max32650evkit/max32650evkit.dts:35 */
		};
	};

	/* node '/buttons' defined in zephyr/boards/adi/max32650evkit/max32650evkit.dts:39 */
	buttons {
		compatible = "gpio-keys"; /* in zephyr/boards/adi/max32650evkit/max32650evkit.dts:40 */

		/* node '/buttons/pb1' defined in zephyr/boards/adi/max32650evkit/max32650evkit.dts:42 */
		pb1: pb1 {
			gpios = < &gpio2 0x1c 0x11 >; /* in zephyr/boards/adi/max32650evkit/max32650evkit.dts:43 */
			label = "SW2";                /* in zephyr/boards/adi/max32650evkit/max32650evkit.dts:44 */
			zephyr,code = < 0xb >;        /* in zephyr/boards/adi/max32650evkit/max32650evkit.dts:45 */
		};

		/* node '/buttons/pb2' defined in zephyr/boards/adi/max32650evkit/max32650evkit.dts:48 */
		pb2: pb2 {
			gpios = < &gpio2 0x1e 0x11 >; /* in zephyr/boards/adi/max32650evkit/max32650evkit.dts:49 */
			label = "SW3";                /* in zephyr/boards/adi/max32650evkit/max32650evkit.dts:50 */
			zephyr,code = < 0x2 >;        /* in zephyr/boards/adi/max32650evkit/max32650evkit.dts:51 */
		};
	};
};
